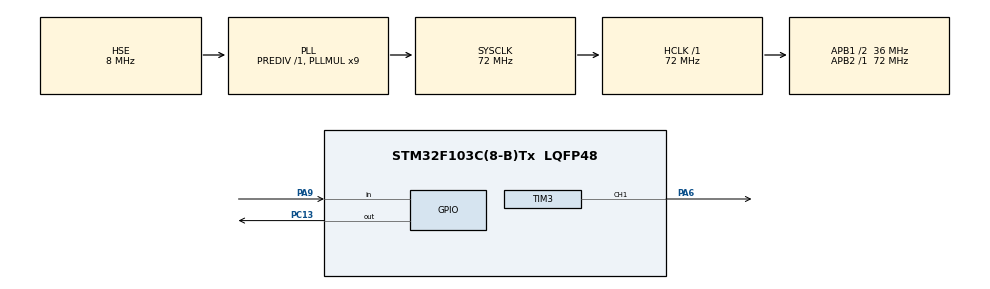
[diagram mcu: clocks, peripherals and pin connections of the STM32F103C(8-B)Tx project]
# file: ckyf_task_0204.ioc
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Mcu.Family=STM32F1
Mcu.Name=STM32F103C(8-B)Tx
Mcu.Package=LQFP48
NVIC.PriorityGroup=NVIC_PRIORITYGROUP_4
NVIC.TIM3_IRQn=true\:0\:0\:false\:false\:true\:true\:true\:true
PA13.Mode=Serial_Wire
PA13.Signal=SYS_JTMS-SWDIO
PA14.Mode=Serial_Wire
PA14.Signal=SYS_JTCK-SWCLK
PA6.Signal=S_TIM3_CH1
PA9.GPIO_PuPd=GPIO_PULLUP
PA9.Signal=GPIO_Input
PC13-TAMPER-RTC.GPIO_ModeDefaultOutputPP=GPIO_MODE_OUTPUT_OD
PC13-TAMPER-RTC.GPIO_PuPd=GPIO_NOPULL
PC13-TAMPER-RTC.Signal=GPIO_Output
PD0-OSC_IN.Mode=HSE-External-Oscillator
PD0-OSC_IN.Signal=RCC_OSC_IN
PD1-OSC_OUT.Mode=HSE-External-Oscillator
PD1-OSC_OUT.Signal=RCC_OSC_OUT
ProjectManager.HeapSize=0x200
ProjectManager.StackSize=0x400
ProjectManager.TargetToolchain=MDK-ARM V5.32
RCC.AHBFreq_Value=72000000
RCC.APB1CLKDivider=RCC_HCLK_DIV2
RCC.APB1Freq_Value=36000000
RCC.APB1TimFreq_Value=72000000
RCC.APB2Freq_Value=72000000
RCC.APB2TimFreq_Value=72000000
RCC.HCLKFreq_Value=72000000
RCC.PLLMUL=RCC_PLL_MUL9
RCC.PLLSourceVirtual=RCC_PLLSOURCE_HSE
RCC.SYSCLKFreq_VALUE=72000000
RCC.SYSCLKSource=RCC_SYSCLKSOURCE_PLLCLK
RCC.USBFreq_Value=72000000
SH.S_TIM3_CH1.0=TIM3_CH1,PWM Generation1 CH1
TIM3.AutoReloadPreload=TIM_AUTORELOAD_PRELOAD_ENABLE
TIM3.Channel-PWM\ Generation1\ CH1=TIM_CHANNEL_1
TIM3.Period=999
TIM3.Prescaler=71
VP_TIM3_VS_ClockSourceINT.Mode=Internal
board=custom

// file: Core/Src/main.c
/* USER CODE BEGIN Header */
/**
  ******************************************************************************
  * @file           : main.c
  * @brief          : Main program body
  ******************************************************************************
  * @attention
  *
  * Copyright (c) 2026 STMicroelectronics.
  * All rights reserved.
  *
  * This software is licensed under terms that can be found in the LICENSE file
  * in the root directory of this software component.
  * If no LICENSE file comes with this software, it is provided AS-IS.
  *
  ******************************************************************************
  */
/* USER CODE END Header */
#include "main.h"

TIM_HandleTypeDef htim3;

/* USER CODE BEGIN PV */
uint8_t mode=0;//0 = 25%  1 = 50%  2 = 75%  3 = 100%  4 = 呼吸灯
uint8_t led=0;//0 = 灭  1 = 亮
uint16_t ccr=0;//灯亮度对应的ccr
volatile uint8_t shortflag=0;//flag是标志
volatile uint8_t longflag=0;
static uint8_t count=0;//count是计数器(用于消抖)
static uint8_t press=0;//press判断是否按下按钮(0是"否", 1是"是")
static uint16_t time=0;//按下的时间
/* USER CODE END PV */

void SystemClock_Config(void);
static void MX_GPIO_Init(void);
static void MX_TIM3_Init(void);

int main(void)
{

  /* MCU Configuration--------------------------------------------------------*/

  /* Reset of all peripherals, Initializes the Flash interface and the Systick. */
  HAL_Init();

  /* Configure the system clock */
  SystemClock_Config();

  /* Initialize all configured peripherals */
  MX_GPIO_Init();
  MX_TIM3_Init();
  /* USER CODE BEGIN 2 */
	HAL_TIM_Base_Start_IT(&htim3);//启动TIM3
	HAL_TIM_PWM_Start(&htim3 ,TIM_CHANNEL_1);//启动TIM3的频道1
  /* USER CODE END 2 */

  /* Infinite loop */
  /* USER CODE BEGIN WHILE */
  while (1)
  {
		if(shortflag == 1)
		{
			shortflag=0;
			if(mode != 4)
			{
				mode++;
				if(mode>3)
				{
					mode=0;//超过100%之后回到25%
				}
				if(mode == 0)
					ccr=250;
				if(mode == 1)
					ccr=500;
				if(mode == 2)
					ccr=750;
				if(mode == 3)
					ccr=1000;
				__HAL_TIM_SET_COMPARE(&htim3 ,TIM_CHANNEL_1 ,ccr);
			}
		}
		if(longflag == 1)
		{
			longflag=0;
			if(mode != 4)
			{
				mode=4;
			}
			else
			{
				mode=0;
				__HAL_TIM_SET_COMPARE(&htim3 ,TIM_CHANNEL_1 ,250);//回到25%
			}
		}
		//以下为呼吸灯(从task0202里面ctrl+c的)
		if(mode == 4)
		{
			static int CCR=0 ,way=0;
			static uint32_t t=0;//t是上次改变亮度的时间
			if(HAL_GetTick()-t>=10)
			{
				t=HAL_GetTick();
				CCR += (way*10);
				if(CCR>=1000)
				{
					CCR=1000;
					way=-1;
				}
				if(CCR<=0)
				{
					CCR=0;
					way=1;
				}
				__HAL_TIM_SET_COMPARE(&htim3 ,TIM_CHANNEL_1 ,CCR);
			}
		}
    /* USER CODE END WHILE */

  }
}

void SystemClock_Config(void)
{
  RCC_OscInitTypeDef RCC_OscInitStruct = {0};
  RCC_ClkInitTypeDef RCC_ClkInitStruct = {0};

  /** Initializes the RCC Oscillators according to the specified parameters
  * in the RCC_OscInitTypeDef structure.
  */
  RCC_OscInitStruct.OscillatorType = RCC_OSCILLATORTYPE_HSE;
  RCC_OscInitStruct.HSEState = RCC_HSE_ON;
  RCC_OscInitStruct.HSEPredivValue = RCC_HSE_PREDIV_DIV1;
  RCC_OscInitStruct.HSIState = RCC_HSI_ON;
  RCC_OscInitStruct.PLL.PLLState = RCC_PLL_ON;
  RCC_OscInitStruct.PLL.PLLSource = RCC_PLLSOURCE_HSE;
  RCC_OscInitStruct.PLL.PLLMUL = RCC_PLL_MUL9;
  if (HAL_RCC_OscConfig(&RCC_OscInitStruct) != HAL_OK)
  {
    Error_Handler();
  }

  /** Initializes the CPU, AHB and APB buses clocks
  */
  RCC_ClkInitStruct.ClockType = RCC_CLOCKTYPE_HCLK|RCC_CLOCKTYPE_SYSCLK
                              |RCC_CLOCKTYPE_PCLK1|RCC_CLOCKTYPE_PCLK2;
  RCC_ClkInitStruct.SYSCLKSource = RCC_SYSCLKSOURCE_PLLCLK;
  RCC_ClkInitStruct.AHBCLKDivider = RCC_SYSCLK_DIV1;
  RCC_ClkInitStruct.APB1CLKDivider = RCC_HCLK_DIV2;
  RCC_ClkInitStruct.APB2CLKDivider = RCC_HCLK_DIV1;

  if (HAL_RCC_ClockConfig(&RCC_ClkInitStruct, FLASH_LATENCY_2) != HAL_OK)
  {
    Error_Handler();
  }
}

static void MX_TIM3_Init(void)
{

  TIM_ClockConfigTypeDef sClockSourceConfig = {0};
  TIM_MasterConfigTypeDef sMasterConfig = {0};
  TIM_OC_InitTypeDef sConfigOC = {0};

  htim3.Instance = TIM3;
  htim3.Init.Prescaler = 71;
  htim3.Init.CounterMode = TIM_COUNTERMODE_UP;
  htim3.Init.Period = 999;
  htim3.Init.ClockDivision = TIM_CLOCKDIVISION_DIV1;
  htim3.Init.AutoReloadPreload = TIM_AUTORELOAD_PRELOAD_ENABLE;
  if (HAL_TIM_Base_Init(&htim3) != HAL_OK)
  {
    Error_Handler();
  }
  sClockSourceConfig.ClockSource = TIM_CLOCKSOURCE_INTERNAL;
  if (HAL_TIM_ConfigClockSource(&htim3, &sClockSourceConfig) != HAL_OK)
  {
    Error_Handler();
  }
  if (HAL_TIM_PWM_Init(&htim3) != HAL_OK)
  {
    Error_Handler();
  }
  sMasterConfig.MasterOutputTrigger = TIM_TRGO_RESET;
  sMasterConfig.MasterSlaveMode = TIM_MASTERSLAVEMODE_DISABLE;
  if (HAL_TIMEx_MasterConfigSynchronization(&htim3, &sMasterConfig) != HAL_OK)
  {
    Error_Handler();
  }
  sConfigOC.OCMode = TIM_OCMODE_PWM1;
  sConfigOC.Pulse = 0;
  sConfigOC.OCPolarity = TIM_OCPOLARITY_HIGH;
  sConfigOC.OCFastMode = TIM_OCFAST_DISABLE;
  if (HAL_TIM_PWM_ConfigChannel(&htim3, &sConfigOC, TIM_CHANNEL_1) != HAL_OK)
  {
    Error_Handler();
  }
  HAL_TIM_MspPostInit(&htim3);

}

static void MX_GPIO_Init(void)
{
  GPIO_InitTypeDef GPIO_InitStruct = {0};

  /* GPIO Ports Clock Enable */
  __HAL_RCC_GPIOC_CLK_ENABLE();
  __HAL_RCC_GPIOD_CLK_ENABLE();
  __HAL_RCC_GPIOA_CLK_ENABLE();

  /*Configure GPIO pin Output Level */
  HAL_GPIO_WritePin(GPIOC, GPIO_PIN_13, GPIO_PIN_RESET);

  /*Configure GPIO pin : PC13 */
  GPIO_InitStruct.Pin = GPIO_PIN_13;
  GPIO_InitStruct.Mode = GPIO_MODE_OUTPUT_OD;
  GPIO_InitStruct.Pull = GPIO_NOPULL;
  GPIO_InitStruct.Speed = GPIO_SPEED_FREQ_LOW;
  HAL_GPIO_Init(GPIOC, &GPIO_InitStruct);

  /*Configure GPIO pin : PA9 */
  GPIO_InitStruct.Pin = GPIO_PIN_9;
  GPIO_InitStruct.Mode = GPIO_MODE_INPUT;
  GPIO_InitStruct.Pull = GPIO_PULLUP;
  HAL_GPIO_Init(GPIOA, &GPIO_InitStruct);

}

/* USER CODE BEGIN 4 */
void HAL_TIM_PeriodElapsedCallback(TIM_HandleTypeDef *htim)
{
	if(htim->Instance == TIM3)
	{
		if(HAL_GPIO_ReadPin(GPIOA ,GPIO_PIN_9) == GPIO_PIN_RESET)
		{
			count++;
			if(count>=20)//after 20 times = safe
			{
				count=20;
				if(press == 0)
				{
					press=1;//按下去了
					time=0;//开始计时
				}
				else
				{
					time++;
				}
			}
		}
		else//松手之后
		{
			count=0;//清空count
			if(press == 1)
			{
				press=0;//恢复
				if(time<1000)
				{
					shortflag=1;//短按完成 1 次:)
				}
				else
				{
					longflag=1;//长按完成 1 次
				}
			}
		}
	}
}
/* USER CODE END 4 */

void Error_Handler(void)
{
  __disable_irq();
  while (1)
  {
  }
}
